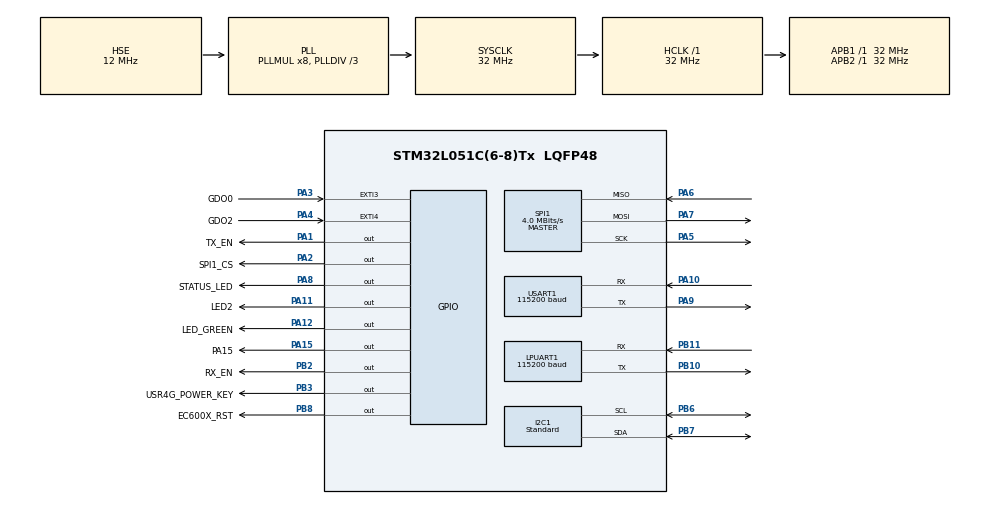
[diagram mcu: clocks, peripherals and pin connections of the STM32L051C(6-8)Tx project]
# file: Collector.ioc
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CRC.DefaultInitValueUse=DEFAULT_INIT_VALUE_ENABLE
CRC.DefaultPolynomialUse=DEFAULT_POLYNOMIAL_ENABLE
CRC.InputDataFormat=CRC_INPUTDATA_FORMAT_BYTES
CRC.InputDataInversionMode=CRC_INPUTDATA_INVERSION_BYTE
CRC.OutputDataInversionMode=CRC_OUTPUTDATA_INVERSION_ENABLE
Dma.Request0=USART1_RX
Dma.Request1=USART1_TX
Dma.USART1_RX.0.Direction=DMA_PERIPH_TO_MEMORY
Dma.USART1_RX.0.Instance=DMA1_Channel3
Dma.USART1_RX.0.MemDataAlignment=DMA_MDATAALIGN_BYTE
Dma.USART1_RX.0.MemInc=DMA_MINC_ENABLE
Dma.USART1_RX.0.Mode=DMA_CIRCULAR
Dma.USART1_RX.0.PeriphDataAlignment=DMA_PDATAALIGN_BYTE
Dma.USART1_RX.0.PeriphInc=DMA_PINC_DISABLE
Dma.USART1_RX.0.Priority=DMA_PRIORITY_LOW
Dma.USART1_TX.1.Direction=DMA_MEMORY_TO_PERIPH
Dma.USART1_TX.1.Instance=DMA1_Channel2
Dma.USART1_TX.1.MemDataAlignment=DMA_MDATAALIGN_BYTE
Dma.USART1_TX.1.MemInc=DMA_MINC_ENABLE
Dma.USART1_TX.1.Mode=DMA_NORMAL
Dma.USART1_TX.1.PeriphDataAlignment=DMA_PDATAALIGN_BYTE
Dma.USART1_TX.1.PeriphInc=DMA_PINC_DISABLE
Dma.USART1_TX.1.Priority=DMA_PRIORITY_LOW
FREERTOS.INCLUDE_uxTaskGetStackHighWaterMark=1
FREERTOS.Mutexes01=linkTxMutex,Static,linkTxMutexControlBlock
FREERTOS.Tasks01=radioTask,40,160,Radio_Task,As external,NULL,Static,radioTaskBuffer,radioTaskControlBlock;linkTask,32,160,Link_Task,As external,NULL,Static,linkTaskBuffer,linkTaskControlBlock;houseTask,24,160,Housekeeping_Task,As external,NULL,Static,houseTaskBuffer,houseTaskControlBlock
FREERTOS.configCHECK_FOR_STACK_OVERFLOW=2
FREERTOS.configMINIMAL_STACK_SIZE=128
FREERTOS.configQUEUE_REGISTRY_SIZE=0
FREERTOS.configTIMER_QUEUE_LENGTH=2
FREERTOS.configTIMER_TASK_STACK_DEPTH=128
FREERTOS.configTOTAL_HEAP_SIZE=512
FREERTOS.configUSE_IDLE_HOOK=1
FREERTOS.configUSE_MALLOC_FAILED_HOOK=1
I2C1.I2C_Speed_Mode=I2C_Standard
I2C1.Timing=0x70420F13
IWDG.Prescaler=IWDG_PRESCALER_256
LPUART1.BaudRate=115200
LPUART1.OneBitSampling=UART_ONE_BIT_SAMPLE_DISABLE
LPUART1.WordLength=UART_WORDLENGTH_8B
Mcu.Family=STM32L0
Mcu.Name=STM32L051C(6-8)Tx
Mcu.Package=LQFP48
NVIC.DMA1_Channel2_3_IRQn=true\:3\:0\:false\:false\:true\:true\:false\:true\:true
NVIC.EXTI2_3_IRQn=true\:3\:0\:true\:false\:true\:true\:true\:true\:true
NVIC.EXTI4_15_IRQn=true\:3\:0\:true\:false\:true\:true\:true\:true\:true
NVIC.LPUART1_IRQn=true\:3\:0\:false\:false\:true\:true\:true\:true\:true
NVIC.TIM2_IRQn=true\:3\:0\:true\:false\:true\:false\:false\:true\:true
NVIC.TimeBase=TIM2_IRQn
NVIC.TimeBaseIP=TIM2
NVIC.USART1_IRQn=true\:3\:0\:false\:false\:true\:true\:true\:true\:true
PA1.GPIO_Label=TX_EN
PA1.Signal=GPIO_Output
PA10.Mode=Asynchronous
PA10.Signal=USART1_RX
PA11.GPIO_Label=LED2
PA11.Signal=GPIO_Output
PA12.GPIO_Label=LED_GREEN
PA12.Signal=GPIO_Output
PA13.Mode=Serial_Wire
PA13.Signal=SYS_SWDIO
PA14.Mode=Serial_Wire
PA14.Signal=SYS_SWCLK
PA15.GPIO_Label=PA15
PA15.Signal=GPIO_Output
PA2.GPIO_Label=SPI1_CS
PA2.GPIO_PuPd=GPIO_PULLUP
PA2.PinState=GPIO_PIN_SET
PA2.Signal=GPIO_Output
PA3.GPIO_Label=GDO0
PA3.GPIO_ModeDefaultEXTI=GPIO_MODE_IT_RISING_FALLING
PA3.GPIO_PuPd=GPIO_NOPULL
PA3.Signal=GPXTI3
PA4.GPIO_Label=GDO2
PA4.GPIO_ModeDefaultEXTI=GPIO_MODE_IT_FALLING
PA4.GPIO_PuPd=GPIO_NOPULL
PA4.Signal=GPXTI4
PA5.Mode=Full_Duplex_Master
PA5.Signal=SPI1_SCK
PA6.Mode=Full_Duplex_Master
PA6.Signal=SPI1_MISO
PA7.Mode=Full_Duplex_Master
PA7.Signal=SPI1_MOSI
PA8.GPIO_Label=STATUS_LED
PA8.Signal=GPIO_Output
PA9.Mode=Asynchronous
PA9.Signal=USART1_TX
PB10.Mode=Asynchronous
PB10.Signal=LPUART1_TX
PB11.Mode=Asynchronous
PB11.Signal=LPUART1_RX
PB2.GPIO_Label=RX_EN
PB2.GPIO_PuPd=GPIO_NOPULL
PB2.PinState=GPIO_PIN_RESET
PB2.Signal=GPIO_Output
PB3.GPIO_Label=USR4G_POWER_KEY
PB3.GPIO_ModeDefaultOutputPP=GPIO_MODE_OUTPUT_PP
PB3.GPIO_PuPd=GPIO_PULLDOWN
PB3.PinState=GPIO_PIN_SET
PB3.Signal=GPIO_Output
PB6.Mode=I2C
PB6.Signal=I2C1_SCL
PB7.Mode=I2C
PB7.Signal=I2C1_SDA
PB8.GPIO_Label=EC600X_RST
PB8.GPIO_PuPd=GPIO_PULLUP
PB8.PinState=GPIO_PIN_SET
PB8.Signal=GPIO_Output
PC14-OSC32_IN.Mode=LSE-External-Oscillator
PC14-OSC32_IN.Signal=RCC_OSC32_IN
PC15-OSC32_OUT.Mode=LSE-External-Oscillator
PC15-OSC32_OUT.Signal=RCC_OSC32_OUT
PH0-OSC_IN.Mode=HSE-External-Oscillator
PH0-OSC_IN.Signal=RCC_OSC_IN
PH1-OSC_OUT.Mode=HSE-External-Oscillator
PH1-OSC_OUT.Signal=RCC_OSC_OUT
ProjectManager.HeapSize=0x0
ProjectManager.StackSize=0x300
ProjectManager.TargetToolchain=CMake
RCC.AHBFreq_Value=32000000
RCC.APB1Freq_Value=32000000
RCC.APB1TimFreq_Value=32000000
RCC.APB2Freq_Value=32000000
RCC.APB2TimFreq_Value=32000000
RCC.HCLKFreq_Value=32000000
RCC.HSE_VALUE=12000000
RCC.HSI16_VALUE=16000000
RCC.HSI_VALUE=16000000
RCC.MSI_VALUE=2097000
RCC.PLLDIV=RCC_PLLDIV_3
RCC.PLLMUL=RCC_PLLMUL_8
RCC.PLLSourceVirtual=RCC_PLLSOURCE_HSE
RCC.RTCClockSelection=RCC_RTCCLKSOURCE_LSE
RCC.RTCClockSelectionVirtual=RCC_RTCCLKSOURCE_LSE
RCC.SYSCLKFreq_VALUE=32000000
RCC.SYSCLKSource=RCC_SYSCLKSOURCE_PLLCLK
RCC.VCOOutputFreq_Value=96000000
RTC.Format=RTC_FORMAT_BIN
SPI1.BaudRatePrescaler=SPI_BAUDRATEPRESCALER_8
SPI1.CalculateBaudRate=4.0 MBits/s
SPI1.Direction=SPI_DIRECTION_2LINES
SPI1.Mode=SPI_MODE_MASTER
SPI1.VirtualType=VM_MASTER
USART1.BaudRate=115200
USART1.VirtualMode-Asynchronous=VM_ASYNC
VP_CRC_VS_CRC.Mode=CRC_Activate
VP_FREERTOS_VS_CMSIS_V2.Mode=CMSIS_V2
VP_IWDG_VS_IWDG.Mode=IWDG_Activate
VP_RTC_VS_RTC_Activate.Mode=RTC_Enabled
VP_RTC_VS_RTC_Calendar.Mode=RTC_Calendar
VP_SYS_VS_tim2.Mode=TIM2
board=custom

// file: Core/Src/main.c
/* USER CODE BEGIN Header */
/**
 ******************************************************************************
 * @file           : main.c
 * @brief          : Main program body
 ******************************************************************************
 * @attention
 *
 * <h2><center>&copy; Copyright (c) 2022 STMicroelectronics.
 * All rights reserved.</center></h2>
 *
 * This software component is licensed by ST under Ultimate Liberty license
 * SLA0044, the "License"; You may not use this file except in compliance with
 * the License. You may obtain a copy of the License at:
 *                             www.st.com/SLA0044
 *
 ******************************************************************************
 */
/* USER CODE END Header */
#include "main.h"
#include "cmsis_os.h"
#include "crc.h"
#include "dma.h"
#include "i2c.h"
#include "iwdg.h"
#include "usart.h"
#include "rtc.h"
#include "spi.h"
#include "gpio.h"

/* USER CODE BEGIN Includes */
#include "app_main.h"
/* USER CODE END Includes */

void SystemClock_Config(void);
void MX_FREERTOS_Init(void);

int main(void)
{

  /* MCU Configuration--------------------------------------------------------*/

  /* Reset of all peripherals, Initializes the Flash interface and the Systick. */
  HAL_Init();

  /* Configure the system clock */
  SystemClock_Config();

  /* Initialize all configured peripherals */
  MX_GPIO_Init();
  MX_DMA_Init();
  MX_USART1_UART_Init();
  MX_SPI1_Init();
  MX_IWDG_Init();
  MX_RTC_Init();
  MX_CRC_Init();
  MX_LPUART1_UART_Init();
  MX_I2C1_Init();
  /* USER CODE BEGIN 2 */
  App_Init();
  /* USER CODE END 2 */

  /* Init scheduler */
  osKernelInitialize();  /* Call init function for freertos objects (in cmsis_os2.c) */
  MX_FREERTOS_Init();

  /* Start scheduler */
  osKernelStart();

  /* We should never get here as control is now taken by the scheduler */

  /* Infinite loop */
  while (1)
  {

  }
}

void SystemClock_Config(void)
{
  RCC_OscInitTypeDef RCC_OscInitStruct = {0};
  RCC_ClkInitTypeDef RCC_ClkInitStruct = {0};
  RCC_PeriphCLKInitTypeDef PeriphClkInit = {0};

  /** Configure the main internal regulator output voltage
  */
  __HAL_PWR_VOLTAGESCALING_CONFIG(PWR_REGULATOR_VOLTAGE_SCALE1);

  /** Configure LSE Drive Capability
  */
  HAL_PWR_EnableBkUpAccess();
  __HAL_RCC_LSEDRIVE_CONFIG(RCC_LSEDRIVE_LOW);

  /** Initializes the RCC Oscillators according to the specified parameters
  * in the RCC_OscInitTypeDef structure.
  */
  RCC_OscInitStruct.OscillatorType = RCC_OSCILLATORTYPE_LSI|RCC_OSCILLATORTYPE_HSE
                              |RCC_OSCILLATORTYPE_LSE;
  RCC_OscInitStruct.HSEState = RCC_HSE_ON;
  RCC_OscInitStruct.LSEState = RCC_LSE_ON;
  RCC_OscInitStruct.LSIState = RCC_LSI_ON;
  RCC_OscInitStruct.PLL.PLLState = RCC_PLL_ON;
  RCC_OscInitStruct.PLL.PLLSource = RCC_PLLSOURCE_HSE;
  RCC_OscInitStruct.PLL.PLLMUL = RCC_PLLMUL_8;
  RCC_OscInitStruct.PLL.PLLDIV = RCC_PLLDIV_3;
  if (HAL_RCC_OscConfig(&RCC_OscInitStruct) != HAL_OK)
  {
    Error_Handler();
  }

  /** Initializes the CPU, AHB and APB buses clocks
  */
  RCC_ClkInitStruct.ClockType = RCC_CLOCKTYPE_HCLK|RCC_CLOCKTYPE_SYSCLK
                              |RCC_CLOCKTYPE_PCLK1|RCC_CLOCKTYPE_PCLK2;
  RCC_ClkInitStruct.SYSCLKSource = RCC_SYSCLKSOURCE_PLLCLK;
  RCC_ClkInitStruct.AHBCLKDivider = RCC_SYSCLK_DIV1;
  RCC_ClkInitStruct.APB1CLKDivider = RCC_HCLK_DIV1;
  RCC_ClkInitStruct.APB2CLKDivider = RCC_HCLK_DIV1;

  if (HAL_RCC_ClockConfig(&RCC_ClkInitStruct, FLASH_LATENCY_1) != HAL_OK)
  {
    Error_Handler();
  }
  PeriphClkInit.PeriphClockSelection = RCC_PERIPHCLK_USART1|RCC_PERIPHCLK_LPUART1
                              |RCC_PERIPHCLK_I2C1|RCC_PERIPHCLK_RTC;
  PeriphClkInit.Usart1ClockSelection = RCC_USART1CLKSOURCE_PCLK2;
  PeriphClkInit.Lpuart1ClockSelection = RCC_LPUART1CLKSOURCE_PCLK1;
  PeriphClkInit.I2c1ClockSelection = RCC_I2C1CLKSOURCE_PCLK1;
  PeriphClkInit.RTCClockSelection = RCC_RTCCLKSOURCE_LSE;
  if (HAL_RCCEx_PeriphCLKConfig(&PeriphClkInit) != HAL_OK)
  {
    Error_Handler();
  }
}

void HAL_TIM_PeriodElapsedCallback(TIM_HandleTypeDef *htim)
{
  if (htim->Instance == TIM2)
  {
    HAL_IncTick();
  }
}

void Error_Handler(void)
{
  /* USER CODE BEGIN Error_Handler_Debug */
  App_FatalError(APP_FAULT_HAL_ERROR);
  /* USER CODE END Error_Handler_Debug */
}

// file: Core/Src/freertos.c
/* USER CODE BEGIN Header */
/**
 ******************************************************************************
 * File Name          : freertos.c
 * Description        : Code for freertos applications
 ******************************************************************************
 * @attention
 *
 * <h2><center>&copy; Copyright (c) 2022 STMicroelectronics.
 * All rights reserved.</center></h2>
 *
 * This software component is licensed by ST under Ultimate Liberty license
 * SLA0044, the "License"; You may not use this file except in compliance with
 * the License. You may obtain a copy of the License at:
 *                             www.st.com/SLA0044
 *
 ******************************************************************************
 */
/* USER CODE END Header */

#include "FreeRTOS.h"
#include "task.h"
#include "main.h"
#include "cmsis_os.h"

typedef StaticTask_t osStaticThreadDef_t;

/* Definitions for radioTask */
osThreadId_t radioTaskHandle;
uint32_t radioTaskBuffer[ 160 ];
osStaticThreadDef_t radioTaskControlBlock;
const osThreadAttr_t radioTask_attributes = {
  .name = "radioTask",
  .cb_mem = &radioTaskControlBlock,
  .cb_size = sizeof(radioTaskControlBlock),
  .stack_mem = &radioTaskBuffer[0],
  .stack_size = sizeof(radioTaskBuffer),
  .priority = (osPriority_t) osPriorityHigh,
};
/* Definitions for linkTask */
osThreadId_t linkTaskHandle;
uint32_t linkTaskBuffer[ 160 ];
osStaticThreadDef_t linkTaskControlBlock;
const osThreadAttr_t linkTask_attributes = {
  .name = "linkTask",
  .cb_mem = &linkTaskControlBlock,
  .cb_size = sizeof(linkTaskControlBlock),
  .stack_mem = &linkTaskBuffer[0],
  .stack_size = sizeof(linkTaskBuffer),
  .priority = (osPriority_t) osPriorityAboveNormal,
};
/* Definitions for houseTask */
osThreadId_t houseTaskHandle;
uint32_t houseTaskBuffer[ 160 ];
osStaticThreadDef_t houseTaskControlBlock;
const osThreadAttr_t houseTask_attributes = {
  .name = "houseTask",
  .cb_mem = &houseTaskControlBlock,
  .cb_size = sizeof(houseTaskControlBlock),
  .stack_mem = &houseTaskBuffer[0],
  .stack_size = sizeof(houseTaskBuffer),
  .priority = (osPriority_t) osPriorityNormal,
};
/* Definitions for linkTxMutex */
osMutexId_t linkTxMutexHandle;
const osMutexAttr_t linkTxMutex_attributes = {
  .name = "linkTxMutex"
};

extern void Radio_Task(void *argument);
extern void Link_Task(void *argument);
extern void Housekeeping_Task(void *argument);

void MX_FREERTOS_Init(void); /* (MISRA C 2004 rule 8.1) */

/* Hook prototypes */
void vApplicationIdleHook(void);
void vApplicationStackOverflowHook(xTaskHandle xTask, signed char *pcTaskName);
void vApplicationMallocFailedHook(void);

/* USER CODE BEGIN 2 */
/* The FreeRTOS hooks declared above and the task bodies live in App/app_main.c
   and App/services. */
/* USER CODE END 2 */

void MX_FREERTOS_Init(void) {
  /* Create the mutex(es) */
  /* creation of linkTxMutex */
  linkTxMutexHandle = osMutexNew(&linkTxMutex_attributes);

  /* Create the thread(s) */
  /* creation of radioTask */
  radioTaskHandle = osThreadNew(Radio_Task, NULL, &radioTask_attributes);

  /* creation of linkTask */
  linkTaskHandle = osThreadNew(Link_Task, NULL, &linkTask_attributes);

  /* creation of houseTask */
  houseTaskHandle = osThreadNew(Housekeeping_Task, NULL, &houseTask_attributes);

}

__weak void Radio_Task(void *argument)
{
  for(;;)
  {
    osDelay(1);
  }
}
